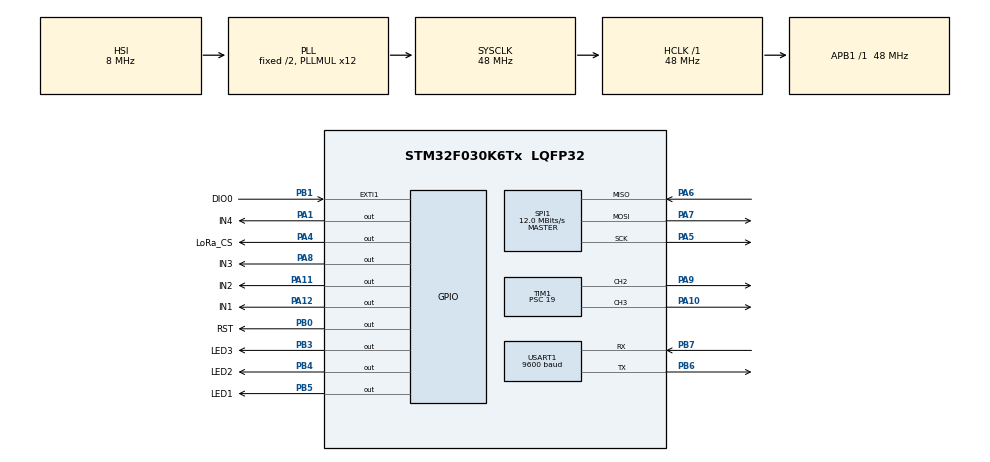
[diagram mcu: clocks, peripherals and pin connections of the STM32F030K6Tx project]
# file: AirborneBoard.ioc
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Dma.Request0=USART1_TX
Dma.Request1=USART1_RX
Dma.USART1_RX.1.Direction=DMA_PERIPH_TO_MEMORY
Dma.USART1_RX.1.Instance=DMA1_Channel3
Dma.USART1_RX.1.MemDataAlignment=DMA_MDATAALIGN_BYTE
Dma.USART1_RX.1.MemInc=DMA_MINC_ENABLE
Dma.USART1_RX.1.Mode=DMA_NORMAL
Dma.USART1_RX.1.PeriphDataAlignment=DMA_PDATAALIGN_BYTE
Dma.USART1_RX.1.PeriphInc=DMA_PINC_DISABLE
Dma.USART1_RX.1.Priority=DMA_PRIORITY_LOW
Dma.USART1_TX.0.Direction=DMA_MEMORY_TO_PERIPH
Dma.USART1_TX.0.Instance=DMA1_Channel2
Dma.USART1_TX.0.MemDataAlignment=DMA_MDATAALIGN_BYTE
Dma.USART1_TX.0.MemInc=DMA_MINC_ENABLE
Dma.USART1_TX.0.Mode=DMA_NORMAL
Dma.USART1_TX.0.PeriphDataAlignment=DMA_PDATAALIGN_BYTE
Dma.USART1_TX.0.PeriphInc=DMA_PINC_DISABLE
Dma.USART1_TX.0.Priority=DMA_PRIORITY_LOW
Mcu.Family=STM32F0
Mcu.Name=STM32F030K6Tx
Mcu.Package=LQFP32
NVIC.DMA1_Channel2_3_IRQn=true\:0\:0\:false\:false\:true\:false\:true
NVIC.EXTI0_1_IRQn=true\:0\:0\:false\:false\:true\:true\:true
NVIC.USART1_IRQn=true\:0\:0\:false\:false\:true\:true\:true
PA1.GPIO_Label=IN4
PA1.Signal=GPIO_Output
PA10.Signal=S_TIM1_CH3
PA11.GPIO_Label=IN2
PA11.Signal=GPIO_Output
PA12.GPIO_Label=IN1
PA12.Signal=GPIO_Output
PA13.Mode=Serial_Wire
PA13.Signal=SYS_SWDIO
PA14.Mode=Serial_Wire
PA14.Signal=SYS_SWCLK
PA4.GPIO_Label=LoRa_CS
PA4.PinState=GPIO_PIN_SET
PA4.Signal=GPIO_Output
PA5.Mode=Full_Duplex_Master
PA5.Signal=SPI1_SCK
PA6.Mode=Full_Duplex_Master
PA6.Signal=SPI1_MISO
PA7.Mode=Full_Duplex_Master
PA7.Signal=SPI1_MOSI
PA8.GPIO_Label=IN3
PA8.Signal=GPIO_Output
PA9.Signal=S_TIM1_CH2
PB0.GPIO_Label=RST
PB0.PinState=GPIO_PIN_SET
PB0.Signal=GPIO_Output
PB1.GPIO_Label=DIO0
PB1.Signal=GPXTI1
PB3.GPIO_Label=LED3
PB3.Signal=GPIO_Output
PB4.GPIO_Label=LED2
PB4.Signal=GPIO_Output
PB5.GPIO_Label=LED1
PB5.Signal=GPIO_Output
PB6.Mode=Asynchronous
PB6.Signal=USART1_TX
PB7.Mode=Asynchronous
PB7.Signal=USART1_RX
ProjectManager.HeapSize=0x200
ProjectManager.StackSize=0x400
ProjectManager.TargetToolchain=SW4STM32
RCC.AHBFreq_Value=48000000
RCC.APB1Freq_Value=48000000
RCC.APB1TimFreq_Value=48000000
RCC.HCLKFreq_Value=48000000
RCC.PLLMUL=RCC_PLL_MUL12
RCC.SYSCLKFreq_VALUE=48000000
RCC.SYSCLKSource=RCC_SYSCLKSOURCE_PLLCLK
SH.S_TIM1_CH2.0=TIM1_CH2,PWM Generation2 CH2
SH.S_TIM1_CH3.0=TIM1_CH3,PWM Generation3 CH3
SPI1.BaudRatePrescaler=SPI_BAUDRATEPRESCALER_4
SPI1.CalculateBaudRate=12.0 MBits/s
SPI1.DataSize=SPI_DATASIZE_8BIT
SPI1.Direction=SPI_DIRECTION_2LINES
SPI1.Mode=SPI_MODE_MASTER
SPI1.VirtualType=VM_MASTER
TIM1.Channel-PWM\ Generation2\ CH2=TIM_CHANNEL_2
TIM1.Channel-PWM\ Generation3\ CH3=TIM_CHANNEL_3
TIM1.Period=1000
TIM1.Prescaler=19
TIM1.Pulse-PWM\ Generation2\ CH2=500
TIM1.Pulse-PWM\ Generation3\ CH3=500
USART1.BaudRate=9600
USART1.VirtualMode-Asynchronous=VM_ASYNC
VP_TIM1_VS_ClockSourceINT.Mode=Internal
board=custom

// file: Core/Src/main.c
/* USER CODE BEGIN Header */
/**
  ******************************************************************************
  * @file           : main.c
  * @brief          : Main program body
  ******************************************************************************
  * @attention
  *
  * <h2><center>&copy; Copyright (c) 2021 STMicroelectronics.
  * All rights reserved.</center></h2>
  *
  * This software component is licensed by ST under BSD 3-Clause license,
  * the "License"; You may not use this file except in compliance with the
  * License. You may obtain a copy of the License at:
  *                        opensource.org/licenses/BSD-3-Clause
  *
  ******************************************************************************
  */
/* USER CODE END Header */
#include "main.h"

SPI_HandleTypeDef hspi1;

TIM_HandleTypeDef htim1;

UART_HandleTypeDef huart1;
DMA_HandleTypeDef hdma_usart1_tx;
DMA_HandleTypeDef hdma_usart1_rx;

void SystemClock_Config(void);
static void MX_GPIO_Init(void);
static void MX_DMA_Init(void);
static void MX_SPI1_Init(void);
static void MX_USART1_UART_Init(void);
static void MX_TIM1_Init(void);
/* USER CODE BEGIN PFP */
void Boot(void);
/* USER CODE END PFP */

int main(void)
{

  /* MCU Configuration--------------------------------------------------------*/

  /* Reset of all peripherals, Initializes the Flash interface and the Systick. */
  HAL_Init();

  /* Configure the system clock */
  SystemClock_Config();

  /* Initialize all configured peripherals */
  MX_GPIO_Init();
  MX_DMA_Init();
  MX_SPI1_Init();
  MX_USART1_UART_Init();
  MX_TIM1_Init();
  /* USER CODE BEGIN 2 */
  Boot();

  /* USER CODE END 2 */

  /* Infinite loop */
  while (1)
  {

  }
}

void SystemClock_Config(void)
{
  RCC_OscInitTypeDef RCC_OscInitStruct = {0};
  RCC_ClkInitTypeDef RCC_ClkInitStruct = {0};
  RCC_PeriphCLKInitTypeDef PeriphClkInit = {0};

  /** Initializes the RCC Oscillators according to the specified parameters
  * in the RCC_OscInitTypeDef structure.
  */
  RCC_OscInitStruct.OscillatorType = RCC_OSCILLATORTYPE_HSI;
  RCC_OscInitStruct.HSIState = RCC_HSI_ON;
  RCC_OscInitStruct.HSICalibrationValue = RCC_HSICALIBRATION_DEFAULT;
  RCC_OscInitStruct.PLL.PLLState = RCC_PLL_ON;
  RCC_OscInitStruct.PLL.PLLSource = RCC_PLLSOURCE_HSI;
  RCC_OscInitStruct.PLL.PLLMUL = RCC_PLL_MUL12;
  RCC_OscInitStruct.PLL.PREDIV = RCC_PREDIV_DIV1;
  if (HAL_RCC_OscConfig(&RCC_OscInitStruct) != HAL_OK)
  {
    Error_Handler();
  }
  /** Initializes the CPU, AHB and APB buses clocks
  */
  RCC_ClkInitStruct.ClockType = RCC_CLOCKTYPE_HCLK|RCC_CLOCKTYPE_SYSCLK
                              |RCC_CLOCKTYPE_PCLK1;
  RCC_ClkInitStruct.SYSCLKSource = RCC_SYSCLKSOURCE_PLLCLK;
  RCC_ClkInitStruct.AHBCLKDivider = RCC_SYSCLK_DIV1;
  RCC_ClkInitStruct.APB1CLKDivider = RCC_HCLK_DIV1;

  if (HAL_RCC_ClockConfig(&RCC_ClkInitStruct, FLASH_LATENCY_1) != HAL_OK)
  {
    Error_Handler();
  }
  PeriphClkInit.PeriphClockSelection = RCC_PERIPHCLK_USART1;
  PeriphClkInit.Usart1ClockSelection = RCC_USART1CLKSOURCE_PCLK1;
  if (HAL_RCCEx_PeriphCLKConfig(&PeriphClkInit) != HAL_OK)
  {
    Error_Handler();
  }
}

static void MX_SPI1_Init(void)
{

  /* SPI1 parameter configuration*/
  hspi1.Instance = SPI1;
  hspi1.Init.Mode = SPI_MODE_MASTER;
  hspi1.Init.Direction = SPI_DIRECTION_2LINES;
  hspi1.Init.DataSize = SPI_DATASIZE_8BIT;
  hspi1.Init.CLKPolarity = SPI_POLARITY_LOW;
  hspi1.Init.CLKPhase = SPI_PHASE_1EDGE;
  hspi1.Init.NSS = SPI_NSS_SOFT;
  hspi1.Init.BaudRatePrescaler = SPI_BAUDRATEPRESCALER_4;
  hspi1.Init.FirstBit = SPI_FIRSTBIT_MSB;
  hspi1.Init.TIMode = SPI_TIMODE_DISABLE;
  hspi1.Init.CRCCalculation = SPI_CRCCALCULATION_DISABLE;
  hspi1.Init.CRCPolynomial = 7;
  hspi1.Init.CRCLength = SPI_CRC_LENGTH_DATASIZE;
  hspi1.Init.NSSPMode = SPI_NSS_PULSE_ENABLE;
  if (HAL_SPI_Init(&hspi1) != HAL_OK)
  {
    Error_Handler();
  }

}

static void MX_TIM1_Init(void)
{

  TIM_ClockConfigTypeDef sClockSourceConfig = {0};
  TIM_MasterConfigTypeDef sMasterConfig = {0};
  TIM_OC_InitTypeDef sConfigOC = {0};
  TIM_BreakDeadTimeConfigTypeDef sBreakDeadTimeConfig = {0};

  htim1.Instance = TIM1;
  htim1.Init.Prescaler = 19;
  htim1.Init.CounterMode = TIM_COUNTERMODE_UP;
  htim1.Init.Period = 1000;
  htim1.Init.ClockDivision = TIM_CLOCKDIVISION_DIV1;
  htim1.Init.RepetitionCounter = 0;
  htim1.Init.AutoReloadPreload = TIM_AUTORELOAD_PRELOAD_DISABLE;
  if (HAL_TIM_Base_Init(&htim1) != HAL_OK)
  {
    Error_Handler();
  }
  sClockSourceConfig.ClockSource = TIM_CLOCKSOURCE_INTERNAL;
  if (HAL_TIM_ConfigClockSource(&htim1, &sClockSourceConfig) != HAL_OK)
  {
    Error_Handler();
  }
  if (HAL_TIM_PWM_Init(&htim1) != HAL_OK)
  {
    Error_Handler();
  }
  sMasterConfig.MasterOutputTrigger = TIM_TRGO_RESET;
  sMasterConfig.MasterSlaveMode = TIM_MASTERSLAVEMODE_DISABLE;
  if (HAL_TIMEx_MasterConfigSynchronization(&htim1, &sMasterConfig) != HAL_OK)
  {
    Error_Handler();
  }
  sConfigOC.OCMode = TIM_OCMODE_PWM1;
  sConfigOC.Pulse = 500;
  sConfigOC.OCPolarity = TIM_OCPOLARITY_HIGH;
  sConfigOC.OCNPolarity = TIM_OCNPOLARITY_HIGH;
  sConfigOC.OCFastMode = TIM_OCFAST_DISABLE;
  sConfigOC.OCIdleState = TIM_OCIDLESTATE_RESET;
  sConfigOC.OCNIdleState = TIM_OCNIDLESTATE_RESET;
  if (HAL_TIM_PWM_ConfigChannel(&htim1, &sConfigOC, TIM_CHANNEL_2) != HAL_OK)
  {
    Error_Handler();
  }
  if (HAL_TIM_PWM_ConfigChannel(&htim1, &sConfigOC, TIM_CHANNEL_3) != HAL_OK)
  {
    Error_Handler();
  }
  sBreakDeadTimeConfig.OffStateRunMode = TIM_OSSR_DISABLE;
  sBreakDeadTimeConfig.OffStateIDLEMode = TIM_OSSI_DISABLE;
  sBreakDeadTimeConfig.LockLevel = TIM_LOCKLEVEL_OFF;
  sBreakDeadTimeConfig.DeadTime = 0;
  sBreakDeadTimeConfig.BreakState = TIM_BREAK_DISABLE;
  sBreakDeadTimeConfig.BreakPolarity = TIM_BREAKPOLARITY_HIGH;
  sBreakDeadTimeConfig.AutomaticOutput = TIM_AUTOMATICOUTPUT_DISABLE;
  if (HAL_TIMEx_ConfigBreakDeadTime(&htim1, &sBreakDeadTimeConfig) != HAL_OK)
  {
    Error_Handler();
  }
  HAL_TIM_MspPostInit(&htim1);

}

static void MX_USART1_UART_Init(void)
{

  huart1.Instance = USART1;
  huart1.Init.BaudRate = 9600;
  huart1.Init.WordLength = UART_WORDLENGTH_8B;
  huart1.Init.StopBits = UART_STOPBITS_1;
  huart1.Init.Parity = UART_PARITY_NONE;
  huart1.Init.Mode = UART_MODE_TX_RX;
  huart1.Init.HwFlowCtl = UART_HWCONTROL_NONE;
  huart1.Init.OverSampling = UART_OVERSAMPLING_16;
  huart1.Init.OneBitSampling = UART_ONE_BIT_SAMPLE_DISABLE;
  huart1.AdvancedInit.AdvFeatureInit = UART_ADVFEATURE_NO_INIT;
  if (HAL_UART_Init(&huart1) != HAL_OK)
  {
    Error_Handler();
  }

}

static void MX_DMA_Init(void)
{

  /* DMA controller clock enable */
  __HAL_RCC_DMA1_CLK_ENABLE();

  /* DMA interrupt init */
  /* DMA1_Channel2_3_IRQn interrupt configuration */
  HAL_NVIC_SetPriority(DMA1_Channel2_3_IRQn, 0, 0);
  HAL_NVIC_EnableIRQ(DMA1_Channel2_3_IRQn);

}

static void MX_GPIO_Init(void)
{
  GPIO_InitTypeDef GPIO_InitStruct = {0};

  /* GPIO Ports Clock Enable */
  __HAL_RCC_GPIOA_CLK_ENABLE();
  __HAL_RCC_GPIOB_CLK_ENABLE();

  /*Configure GPIO pin Output Level */
  HAL_GPIO_WritePin(GPIOA, IN4_Pin|IN3_Pin|IN2_Pin|IN1_Pin, GPIO_PIN_RESET);

  /*Configure GPIO pin Output Level */
  HAL_GPIO_WritePin(LoRa_CS_GPIO_Port, LoRa_CS_Pin, GPIO_PIN_SET);

  /*Configure GPIO pin Output Level */
  HAL_GPIO_WritePin(RST_GPIO_Port, RST_Pin, GPIO_PIN_SET);

  /*Configure GPIO pin Output Level */
  HAL_GPIO_WritePin(GPIOB, LED3_Pin|LED2_Pin|LED1_Pin, GPIO_PIN_RESET);

  /*Configure GPIO pins : IN4_Pin LoRa_CS_Pin IN3_Pin IN2_Pin
                           IN1_Pin */
  GPIO_InitStruct.Pin = IN4_Pin|LoRa_CS_Pin|IN3_Pin|IN2_Pin
                          |IN1_Pin;
  GPIO_InitStruct.Mode = GPIO_MODE_OUTPUT_PP;
  GPIO_InitStruct.Pull = GPIO_NOPULL;
  GPIO_InitStruct.Speed = GPIO_SPEED_FREQ_LOW;
  HAL_GPIO_Init(GPIOA, &GPIO_InitStruct);

  /*Configure GPIO pins : RST_Pin LED3_Pin LED2_Pin LED1_Pin */
  GPIO_InitStruct.Pin = RST_Pin|LED3_Pin|LED2_Pin|LED1_Pin;
  GPIO_InitStruct.Mode = GPIO_MODE_OUTPUT_PP;
  GPIO_InitStruct.Pull = GPIO_NOPULL;
  GPIO_InitStruct.Speed = GPIO_SPEED_FREQ_LOW;
  HAL_GPIO_Init(GPIOB, &GPIO_InitStruct);

  /*Configure GPIO pin : DIO0_Pin */
  GPIO_InitStruct.Pin = DIO0_Pin;
  GPIO_InitStruct.Mode = GPIO_MODE_IT_RISING;
  GPIO_InitStruct.Pull = GPIO_NOPULL;
  HAL_GPIO_Init(DIO0_GPIO_Port, &GPIO_InitStruct);

  /* EXTI interrupt init*/
  HAL_NVIC_SetPriority(EXTI0_1_IRQn, 0, 0);
  HAL_NVIC_EnableIRQ(EXTI0_1_IRQn);

}

void Error_Handler(void)
{
  __disable_irq();
  while (1)
  {
  }
}

/************************ (C) COPYRIGHT STMicroelectronics *****END OF FILE****/
